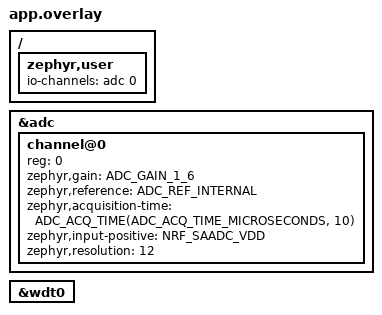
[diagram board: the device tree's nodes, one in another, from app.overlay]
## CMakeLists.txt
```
# SPDX-License-Identifier: Apache-2.0
cmake_minimum_required(VERSION 3.20.0)

# Плата holyiot_21011 описана в этом репозитории (boards/holyiot/holyiot_21011).
list(APPEND BOARD_ROOT ${CMAKE_CURRENT_SOURCE_DIR}/../..)

find_package(Zephyr REQUIRED HINTS $ENV{ZEPHYR_BASE})
project(knife_angle)

target_sources(app PRIVATE
  src/main.c
  src/accel.c
  src/ble.c
  src/calib.c
  src/filter.c
)
```

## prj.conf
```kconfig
# KnifeAngle: основная прошивка (этап 1).

# --- BLE: периферия, одно соединение, без сопряжения ---
CONFIG_BT=y
CONFIG_BT_PERIPHERAL=y
CONFIG_BT_DEVICE_NAME="KnifeAngle"
CONFIG_BT_MAX_CONN=1
CONFIG_BT_SMP=n
CONFIG_BT_BAS=y
# Без сопряжения шифрование и приватность в контроллере не нужны (минус ~10 КБ flash).
CONFIG_BT_CTLR_LE_ENC=n
CONFIG_BT_CTLR_PRIVACY=n

# Параметры соединения, которые устройство запрашивает через 5 с после подключения.
# Интервал 180–200 мс (единицы 1.25 мс): ровно под notify раз в 200 мс, и меньше
# пробуждений радио. Задержка 0, таймаут 4 с.
# Укладывается в требования Apple: min+15 мс ≤ max, max·(lat+1)·3 < timeout.
CONFIG_BT_GAP_AUTO_UPDATE_CONN_PARAMS=y
CONFIG_BT_GAP_PERIPHERAL_PREF_PARAMS=y
CONFIG_BT_PERIPHERAL_PREF_MIN_INT=144
CONFIG_BT_PERIPHERAL_PREF_MAX_INT=160
CONFIG_BT_PERIPHERAL_PREF_LATENCY=0
CONFIG_BT_PERIPHERAL_PREF_TIMEOUT=400

# --- Периферия чипа ---
CONFIG_SPI=y
# Драйвер Zephyr для LIS2DH не нужен: регистры читаются напрямую (accel.c).
CONFIG_LIS2DH=n
CONFIG_ADC=y
CONFIG_WATCHDOG=y
CONFIG_POWEROFF=y

# --- Хранение калибровки: NVS в разделе storage_partition (8 КБ) ---
CONFIG_FLASH=y
CONFIG_FLASH_MAP=y
CONFIG_NVS=y

# --- Прочее ---
CONFIG_LOG=n
CONFIG_ASSERT=n
CONFIG_MAIN_STACK_SIZE=2048
```

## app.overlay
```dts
/ {
	zephyr,user {
		io-channels = <&adc 0>;
	};
};

/* Канал 0 SAADC: напряжение питания VDD (батарея), шкала 0..3.6 В. */
&adc {
	#address-cells = <1>;
	#size-cells = <0>;

	channel@0 {
		reg = <0>;
		zephyr,gain = "ADC_GAIN_1_6";
		zephyr,reference = "ADC_REF_INTERNAL";
		zephyr,acquisition-time = <ADC_ACQ_TIME(ADC_ACQ_TIME_MICROSECONDS, 10)>;
		zephyr,input-positive = <NRF_SAADC_VDD>;
		zephyr,resolution = <12>;
	};
};

&wdt0 {
	status = "okay";
};
```

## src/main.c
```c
/*
 * KnifeAngle: BLE-датчик угла заточки (HOLYIOT-21011, nRF52810 + LIS2DH12).
 *
 * Состояния:
 *   ВЫКЛ: System OFF, датчик обесточен, радио выключено, пробуждение по кнопке.
 *         Пробуждение из System OFF это сброс чипа, поэтому после старта проверяется,
 *         что кнопку держат ≥1.5 с; если нет, чип сразу засыпает обратно.
 *         Любой другой сброс (установка батарейки, перепрошивка, watchdog) тоже ведёт в ВЫКЛ.
 *   ВКЛ:  датчик 25 Гц, реклама «KnifeAngle», при подключении notify угла 5 раз в секунду.
 *
 * Кнопка в ВКЛ: короткое нажатие (<0.8 с) = калибровка, длинное (≥1.5 с) = ВЫКЛ.
 * Светодиод: ВКЛ = одна вспышка 0.5 с, ВЫКЛ = две по 0.15 с,
 *            калибровка = короткая 60 мс, отказ калибровки = три быстрые.
 *
 * SPDX-License-Identifier: Apache-2.0
 */

#include <math.h>
#include <string.h>

#include <zephyr/kernel.h>
#include <zephyr/drivers/adc.h>
#include <zephyr/drivers/gpio.h>
#include <zephyr/drivers/watchdog.h>
#include <zephyr/sys/poweroff.h>
#include <zephyr/sys/util.h>
#include <hal/nrf_power.h>

#include "accel.h"
#include "app.h"
#include "ble.h"
#include "calib.h"
#include "filter.h"

/* Допустимый модуль вектора при калибровке, mg: датчик должен лежать спокойно. */
#define CALIB_MIN_MG 700.0f
#define CALIB_MAX_MG 1300.0f

#define WDT_TIMEOUT_MS 5000

#define RAD_TO_DEG 57.29577951f

static const struct gpio_dt_spec led = GPIO_DT_SPEC_GET(DT_ALIAS(led0), gpios);
static const struct gpio_dt_spec btn = GPIO_DT_SPEC_GET(DT_ALIAS(sw0), gpios);
static const struct adc_dt_spec vdd_adc = ADC_DT_SPEC_GET_BY_IDX(DT_PATH(zephyr_user), 0);
static const struct device *const wdt = DEVICE_DT_GET(DT_NODELABEL(wdt0));

K_MSGQ_DEFINE(evq, sizeof(uint8_t), 16, 1);

void app_post(enum app_event ev)
{
	uint8_t e = ev;

	(void)k_msgq_put(&evq, &e, K_NO_WAIT);
}

/* ------------------------------------------------------------------------ */
/* Светодиод, сторожевой таймер, батарея                                    */
/* ------------------------------------------------------------------------ */

static void led_flash(int n, int on_ms, int off_ms)
{
	for (int i = 0; i < n; i++) {
		gpio_pin_set_dt(&led, 1);
		k_msleep(on_ms);
		gpio_pin_set_dt(&led, 0);
		if (i + 1 < n) {
			k_msleep(off_ms);
		}
	}
}

static int wdt_channel = -1;

static void wdt_start(void)
{
	const struct wdt_timeout_cfg cfg = {
		.window = { .min = 0, .max = WDT_TIMEOUT_MS },
		.flags = WDT_FLAG_RESET_SOC,
	};

	if (!device_is_ready(wdt)) {
		return;
	}
	wdt_channel = wdt_install_timeout(wdt, &cfg);
	if (wdt_channel >= 0) {
		wdt_setup(wdt, WDT_OPT_PAUSE_HALTED_BY_DBG);
	}
}

static void wdt_kick(void)
{
	if (wdt_channel >= 0) {
		wdt_feed(wdt, wdt_channel);
	}
}

/* Грубая кривая разряда CR2032 под малой нагрузкой: мВ → %. */
static uint8_t battery_percent(int32_t mv)
{
	static const struct {
		int16_t mv;
		uint8_t pct;
	} curve[] = {
		{ 3000, 100 }, { 2900, 80 }, { 2800, 60 }, { 2700, 40 },
		{ 2600, 20 },  { 2500, 10 }, { 2400, 5 },  { 2000, 0 },
	};

	if (mv >= curve[0].mv) {
		return 100;
	}
	for (size_t i = 1; i < ARRAY_SIZE(curve); i++) {
		if (mv >= curve[i].mv) {
			int32_t span = curve[i - 1].mv - curve[i].mv;

			return curve[i].pct + (mv - curve[i].mv) *
				(curve[i - 1].pct - curve[i].pct) / span;
		}
	}
	return 0;
}

static void battery_update(void)
{
	int16_t sample;
	struct adc_sequence seq = {
		.buffer = &sample,
		.buffer_size = sizeof(sample),
	};
	int32_t mv;

	adc_sequence_init_dt(&vdd_adc, &seq);
	if (adc_read_dt(&vdd_adc, &seq) != 0) {
		return;
	}
	mv = sample;
	adc_raw_to_millivolts_dt(&vdd_adc, &mv);
	ble_set_battery(battery_percent(mv));
}

/* ------------------------------------------------------------------------ */
/* Кнопка                                                                   */
/* ------------------------------------------------------------------------ */

static int btn_level; /* после антидребезга; меняется только в debounce_handler */
static struct gpio_callback btn_cb;

static void debounce_handler(struct k_work *work)
{
	int level = gpio_pin_get_dt(&btn);

	if (level >= 0 && level != btn_level) {
		btn_level = level;
		app_post(level ? EV_BTN_DOWN : EV_BTN_UP);
	}
}

static K_WORK_DELAYABLE_DEFINE(debounce_work, debounce_handler);

static void btn_isr(const struct device *dev, struct gpio_callback *cb, uint32_t pins)
{
	k_work_reschedule(&debounce_work, K_MSEC(20));
}

static void long_press_expiry(struct k_timer *t)
{
	app_post(EV_BTN_LONG);
}

static K_TIMER_DEFINE(long_press_timer, long_press_expiry, NULL);

static void tick_expiry(struct k_timer *t)
{
	app_post(EV_TICK);
}

static K_TIMER_DEFINE(tick_timer, tick_expiry, NULL);

static bool button_pressed(void)
{
	return gpio_pin_get_dt(&btn) > 0;
}

/* ------------------------------------------------------------------------ */
/* ВЫКЛ                                                                     */
/* ------------------------------------------------------------------------ */

static bool ble_started;

static FUNC_NORETURN void power_off(bool confirm)
{
	k_timer_stop(&tick_timer);
	k_timer_stop(&long_press_timer);
	gpio_pin_interrupt_configure_dt(&btn, GPIO_INT_DISABLE);

	if (ble_started) {
		ble_stop();
	}
	accel_off();

	if (confirm) {
		led_flash(2, 150, 150);
	}

	/* System OFF просыпается по уровню, поэтому сначала ждём отпускания кнопки. */
	while (button_pressed()) {
		wdt_kick();
		k_msleep(20);
	}
	k_msleep(50);

	gpio_pin_interrupt_configure_dt(&btn, GPIO_INT_LEVEL_ACTIVE);
	sys_poweroff();
}

/* ------------------------------------------------------------------------ */
/* Угол                                                                     */
/* ------------------------------------------------------------------------ */

static float ref[3] = { 0.0f, 0.0f, 1.0f }; /* без калибровки: ось Z датчика */
static bool calibrated;
static bool sensor_error;

static void process_samples(void)
{
	int16_t buf[ACCEL_FIFO_DEPTH][3];
	int n;

	if (sensor_error) {
		return;
	}
	n = accel_read_fifo(buf, ACCEL_FIFO_DEPTH);
	if (n < 0) {
		sensor_error = true;
		return;
	}
	for (int i = 0; i < n; i++) {
		filter_add(buf[i]);
	}
}

/* Угол между текущим вектором гравитации и опорным, 0..180°, в единицах 0.1°.
 * atan2(|r×g|, r·g) точнее, чем acos, при углах около 0° и 180°.
 */
static int16_t angle_x10(const float g[3])
{
	float cx = ref[1] * g[2] - ref[2] * g[1];
	float cy = ref[2] * g[0] - ref[0] * g[2];
	float cz = ref[0] * g[1] - ref[1] * g[0];
	float cross = sqrtf(cx * cx + cy * cy + cz * cz);
	float dot = ref[0] * g[0] + ref[1] * g[1] + ref[2] * g[2];

	return (int16_t)lroundf(atan2f(cross, dot) * RAD_TO_DEG * 10.0f);
}

static void publish_angle(void)
{
	uint8_t flags = (calibrated ? ANGLE_FLAG_CALIBRATED : 0) |
			(sensor_error ? ANGLE_FLAG_SENSOR_ERROR : 0);
	float g[3];

	ble_set_angle(filter_get(g) ? angle_x10(g) : 0, flags);
}

static void calibrate(void)
{
	float m;
	float g[3];
	float v[3];

	process_samples(); /* взять самые свежие отсчёты из FIFO */

	if (sensor_error || !filter_get(g)) {
		led_flash(3, 40, 80);
		return;
	}
	m = sqrtf(g[0] * g[0] + g[1] * g[1] + g[2] * g[2]);
	if (m < CALIB_MIN_MG || m > CALIB_MAX_MG) {
		led_flash(3, 40, 80);
		return;
	}
	for (int a = 0; a < 3; a++) {
		v[a] = g[a] / m;
	}
	if (calib_save(v) != 0) {
		led_flash(3, 40, 80);
		return;
	}

	memcpy(ref, v, sizeof(ref));
	calibrated = true;
	led_flash(1, 60, 0);
	publish_angle();
}

/* ------------------------------------------------------------------------ */

static void set_tick(uint32_t period_ms)
{
	k_timer_start(&tick_timer, K_MSEC(period_ms), K_MSEC(period_ms));
}

int main(void)
{
	uint32_t resetreas = NRF_POWER->RESETREAS;
	int64_t press_start = 0;
	int64_t last_conn_activity;
	int64_t last_battery;
	bool ignore_release;
	uint8_t ev;

	NRF_POWER->RESETREAS = resetreas; /* сброс битов записью единиц */

	gpio_pin_configure_dt(&led, GPIO_OUTPUT_INACTIVE);
	gpio_pin_configure_dt(&btn, GPIO_INPUT);

	/* Не пробуждение кнопкой (батарейку вставили, перепрошили, сработал watchdog):
	 * устройство начинает в ВЫКЛ.
	 */
	if (!(resetreas & POWER_RESETREAS_OFF_Msk)) {
		power_off(false);
	}

	/* Пробуждение кнопкой: включаемся, только если её держат ≥1.5 с с момента старта. */
	while (k_uptime_get() < LONG_PRESS_MS) {
		if (!button_pressed()) {
			power_off(false);
		}
		k_msleep(10);
	}

	/* ---- ВКЛ ---- */
	wdt_start();
	led_flash(1, 500, 0);

	/* Нажатие, которым включили, ещё может длиться: его отпускание игнорируем. */
	btn_level = button_pressed();
	ignore_release = btn_level;
	gpio_init_callback(&btn_cb, btn_isr, BIT(btn.pin));
	gpio_add_callback_dt(&btn, &btn_cb);
	gpio_pin_interrupt_configure_dt(&btn, GPIO_INT_EDGE_BOTH);
	/* Перечитать уровень: кнопку могли отпустить до включения прерывания. */
	k_work_reschedule(&debounce_work, K_MSEC(20));

	calibrated = calib_load(ref);
	if (!calibrated) {
		ref[0] = 0.0f;
		ref[1] = 0.0f;
		ref[2] = 1.0f;
	}

	if (accel_on() != 0) {
		sensor_error = true;
		led_flash(5, 40, 120);
	}

	adc_channel_setup_dt(&vdd_adc);

	if (ble_init() != 0) {
		led_flash(10, 40, 80);
		power_off(false);
	}
	ble_started = true;
	battery_update();
	last_battery = k_uptime_get();
	ble_adv_start();

	last_conn_activity = k_uptime_get();
	set_tick(TICK_IDLE_MS);

	while (true) {
		k_msgq_get(&evq, &ev, K_FOREVER);
		int64_t now = k_uptime_get();

		switch (ev) {
		case EV_TICK:
			wdt_kick();
			process_samples();
			publish_angle();
			if (now - last_battery >= BATTERY_PERIOD_MS) {
				battery_update();
				last_battery = now;
			}
			if (!ble_is_connected() && now - last_conn_activity >= AUTO_OFF_NO_CONN_MS) {
				power_off(true);
			}
			break;

		case EV_BTN_DOWN:
			press_start = now;
			k_timer_start(&long_press_timer, K_MSEC(LONG_PRESS_MS), K_NO_WAIT);
			break;

		case EV_BTN_UP:
			k_timer_stop(&long_press_timer);
			if (ignore_release) {
				ignore_release = false;
			} else if (now - press_start < SHORT_PRESS_MS) {
				calibrate();
			}
			break;

		case EV_BTN_LONG:
			if (btn_level && !ignore_release) {
				power_off(true);
			}
			break;

		case EV_CALIBRATE:
			calibrate();
			break;

		case EV_CONNECTED:
			last_conn_activity = now;
			set_tick(TICK_CONNECTED_MS);
			break;

		case EV_DISCONNECTED:
			last_conn_activity = now;
			set_tick(TICK_IDLE_MS);
			break;

		case EV_ADV_RESTART:
			if (!ble_is_connected()) {
				ble_adv_start();
			}
			break;
		}
	}

	return 0;
}
```

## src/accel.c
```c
/*
 * LIS2DH12 по SPI.
 *
 * Датчик питается от P0.08 (LVCC). В ВЫКЛ питание снимается полностью, так что
 * в System OFF датчик ничего не потребляет.
 *
 * Отсчёты копятся во встроенном FIFO (32 уровня) в режиме stream, а прошивка
 * забирает их пачкой раз в 200 мс (при подключении) или раз в 1 с (без него).
 * Так процессор просыпается редко, а фильтр всё равно получает все 25 отсчётов в секунду.
 *
 * SPDX-License-Identifier: Apache-2.0
 */

#include <errno.h>

#include <zephyr/kernel.h>
#include <zephyr/drivers/gpio.h>
#include <zephyr/drivers/spi.h>
#include <zephyr/sys/byteorder.h>
#include <zephyr/sys/util.h>
#include <hal/nrf_gpio.h>

#include "accel.h"

#define REG_WHO_AM_I      0x0F
#define REG_CTRL_REG1     0x20
#define REG_CTRL_REG4     0x23
#define REG_CTRL_REG5     0x24
#define REG_OUT_X_L       0x28
#define REG_FIFO_CTRL_REG 0x2E
#define REG_FIFO_SRC_REG  0x2F

#define WHO_AM_I_VAL 0x33

#define SPI_READ  0x80
#define SPI_MULTI 0x40

/* Линии SPI по схеме (boards/holyiot/holyiot_21011/holyiot_21011-pinctrl.dtsi). */
#define PIN_SCK  5
#define PIN_MOSI 2
#define PIN_MISO 3

#define ACCEL_NODE DT_NODELABEL(lis2dh12)

/* LIS2DH12: SPI режим 3 (SCK в покое высокий), старший бит первым. */
static const struct spi_dt_spec spi = SPI_DT_SPEC_GET(
	ACCEL_NODE, SPI_WORD_SET(8) | SPI_TRANSFER_MSB | SPI_MODE_CPOL | SPI_MODE_CPHA);

static const struct gpio_dt_spec pwr = GPIO_DT_SPEC_GET(DT_PATH(zephyr_user), accel_power_gpios);

static int reg_read(uint8_t reg, uint8_t *buf, size_t len)
{
	uint8_t cmd = SPI_READ | (len > 1 ? SPI_MULTI : 0) | reg;
	const struct spi_buf tx_buf = { .buf = &cmd, .len = 1 };
	const struct spi_buf_set tx = { .buffers = &tx_buf, .count = 1 };
	struct spi_buf rx_bufs[] = {
		{ .buf = NULL, .len = 1 }, /* байт во время передачи команды */
		{ .buf = buf, .len = len },
	};
	const struct spi_buf_set rx = { .buffers = rx_bufs, .count = ARRAY_SIZE(rx_bufs) };

	return spi_transceive_dt(&spi, &tx, &rx);
}

static int reg_write(uint8_t reg, uint8_t val)
{
	uint8_t data[2] = { reg, val };
	const struct spi_buf tx_buf = { .buf = data, .len = sizeof(data) };
	const struct spi_buf_set tx = { .buffers = &tx_buf, .count = 1 };

	return spi_write_dt(&spi, &tx);
}

int accel_on(void)
{
	uint8_t who = 0;
	int err;

	if (!spi_is_ready_dt(&spi) || !gpio_is_ready_dt(&pwr)) {
		return -ENODEV;
	}

	gpio_pin_configure_dt(&pwr, GPIO_OUTPUT_ACTIVE);
	k_msleep(10); /* загрузка после подачи питания: 5 мс по даташиту */

	err = reg_read(REG_WHO_AM_I, &who, 1);
	if (err) {
		return err;
	}
	if (who != WHO_AM_I_VAL) {
		return -ENODEV;
	}

	/* Порядок: сначала FIFO в bypass (сброс), потом настройка, потом stream. */
	err = reg_write(REG_FIFO_CTRL_REG, 0x00);
	/* ±4 g, а не ±2 g: при штрихах гравитация плюс ускорение и вибрация от камня
	 * могут выйти за 2 g по оси, а срезанные пики смещают среднее.
	 */
	err |= reg_write(REG_CTRL_REG4, 0x98); /* BDU=1, ±4 g, HR=1 (12 бит, 2 mg/LSB) */
	err |= reg_write(REG_CTRL_REG5, 0x40); /* FIFO_EN */
	err |= reg_write(REG_FIFO_CTRL_REG, 0x80); /* stream: при переполнении старые отсчёты затираются */
	err |= reg_write(REG_CTRL_REG1, 0x37); /* ODR 25 Гц, X/Y/Z включены */

	return err ? -EIO : 0;
}

int accel_read_fifo(int16_t mg[][3], int max)
{
	uint8_t src;
	uint8_t raw[6];
	int n;

	if (reg_read(REG_FIFO_SRC_REG, &src, 1)) {
		return -EIO;
	}

	/* FSS: число непрочитанных отсчётов; OVRN: FIFO полон (32). */
	n = (src & BIT(6)) ? ACCEL_FIFO_DEPTH : (src & 0x1F);
	n = MIN(n, max);

	for (int i = 0; i < n; i++) {
		/* Чтение 6 байт с 0x28 забирает из FIFO один отсчёт X/Y/Z. */
		if (reg_read(REG_OUT_X_L, raw, sizeof(raw))) {
			return -EIO;
		}
		for (int a = 0; a < 3; a++) {
			/* Данные 12-битные, выровнены влево; 2 mg на единицу при ±4 g. */
			mg[i][a] = ((int16_t)sys_get_le16(&raw[2 * a]) >> 4) * 2;
		}
	}

	return n;
}

void accel_off(void)
{
	(void)reg_write(REG_CTRL_REG1, 0x00); /* power-down */

	/* Снять питание и отпустить все линии датчика: высокий уровень на CS или SCK
	 * при обесточенном датчике подпитывал бы его через защитные диоды.
	 */
	gpio_pin_configure_dt(&pwr, GPIO_OUTPUT_INACTIVE);
	gpio_pin_configure_dt(&spi.config.cs.gpio, GPIO_DISCONNECTED);
	nrf_gpio_cfg_default(PIN_SCK);
	nrf_gpio_cfg_default(PIN_MOSI);
	nrf_gpio_cfg_default(PIN_MISO);
}
```

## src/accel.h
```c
/*
 * LIS2DH12 по SPI: питание через GPIO, FIFO в режиме stream.
 * SPDX-License-Identifier: Apache-2.0
 */

#ifndef KNIFE_ACCEL_H_
#define KNIFE_ACCEL_H_

#include <stdint.h>

/* Частота выборки датчика, Гц. */
#define ACCEL_ODR_HZ 25

/* Ёмкость FIFO LIS2DH12. */
#define ACCEL_FIFO_DEPTH 32

/* Подать питание, проверить WHO_AM_I и запустить: 25 Гц, ±4 g, HR, FIFO stream. */
int accel_on(void);

/* Забрать накопленные отсчёты (mg) из FIFO. Возвращает их число (0..32) или <0. */
int accel_read_fifo(int16_t mg[][3], int max);

/* Перевести датчик в power-down, снять питание и отпустить линии SPI. */
void accel_off(void);

#endif /* KNIFE_ACCEL_H_ */
```

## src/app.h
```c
/*
 * KnifeAngle: общие определения.
 * SPDX-License-Identifier: Apache-2.0
 */

#ifndef KNIFE_APP_H_
#define KNIFE_APP_H_

#include <stdint.h>

/* Время без подключения до автоматического выключения. */
#define AUTO_OFF_NO_CONN_MS (10 * 60 * 1000)

/* Кнопка. */
#define LONG_PRESS_MS  1500 /* ВКЛ/ВЫКЛ */
#define SHORT_PRESS_MS 800  /* короче: калибровка */

/* Период обработки: при подключении это и период notify (5 Гц). */
#define TICK_CONNECTED_MS 200
#define TICK_IDLE_MS      1000 /* без подключения FIFO датчика (32 отсчёта = 1.28 с) читается реже */

/* Период измерения батареи. */
#define BATTERY_PERIOD_MS (60 * 1000)

/* Биты поля flags в характеристике Angle. */
#define ANGLE_FLAG_CALIBRATED   0x01
#define ANGLE_FLAG_SENSOR_ERROR 0x02

/* События главного цикла. */
enum app_event {
	EV_TICK,
	EV_BTN_DOWN,
	EV_BTN_UP,
	EV_BTN_LONG,
	EV_CALIBRATE,
	EV_CONNECTED,
	EV_DISCONNECTED,
	EV_ADV_RESTART,
};

void app_post(enum app_event ev);

#endif /* KNIFE_APP_H_ */
```

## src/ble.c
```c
/*
 * BLE: реклама «KnifeAngle», сервис с характеристиками Angle и Command, Battery Service.
 * SPDX-License-Identifier: Apache-2.0
 */

#include <errno.h>

#include <zephyr/kernel.h>
#include <zephyr/bluetooth/bluetooth.h>
#include <zephyr/bluetooth/conn.h>
#include <zephyr/bluetooth/gatt.h>
#include <zephyr/bluetooth/hci.h>
#include <zephyr/bluetooth/uuid.h>
#include <zephyr/bluetooth/services/bas.h>
#include <zephyr/sys/byteorder.h>

#include "app.h"
#include "ble.h"

static const struct bt_uuid_128 ka_svc_uuid = BT_UUID_INIT_128(KA_UUID_SVC_VAL);
static const struct bt_uuid_128 ka_angle_uuid = BT_UUID_INIT_128(KA_UUID_ANGLE_VAL);
static const struct bt_uuid_128 ka_cmd_uuid = BT_UUID_INIT_128(KA_UUID_COMMAND_VAL);

static uint8_t angle_val[3]; /* int16 LE угол ×10 + uint8 flags */
static bool notify_enabled;
static struct bt_conn *cur_conn;

static ssize_t angle_read(struct bt_conn *conn, const struct bt_gatt_attr *attr, void *buf,
			  uint16_t len, uint16_t offset)
{
	return bt_gatt_attr_read(conn, attr, buf, len, offset, angle_val, sizeof(angle_val));
}

static void angle_ccc_changed(const struct bt_gatt_attr *attr, uint16_t value)
{
	notify_enabled = (value == BT_GATT_CCC_NOTIFY);
}

static ssize_t cmd_write(struct bt_conn *conn, const struct bt_gatt_attr *attr, const void *buf,
			 uint16_t len, uint16_t offset, uint8_t flags)
{
	if (offset != 0 || len != 1) {
		return BT_GATT_ERR(BT_ATT_ERR_INVALID_ATTRIBUTE_LEN);
	}

	switch (((const uint8_t *)buf)[0]) {
	case KA_CMD_CALIBRATE:
		app_post(EV_CALIBRATE);
		return len;
	default:
		return BT_GATT_ERR(BT_ATT_ERR_VALUE_NOT_ALLOWED);
	}
}

BT_GATT_SERVICE_DEFINE(ka_svc,
	BT_GATT_PRIMARY_SERVICE(&ka_svc_uuid),
	BT_GATT_CHARACTERISTIC(&ka_angle_uuid.uuid, BT_GATT_CHRC_READ | BT_GATT_CHRC_NOTIFY,
			       BT_GATT_PERM_READ, angle_read, NULL, NULL),
	BT_GATT_CCC(angle_ccc_changed, BT_GATT_PERM_READ | BT_GATT_PERM_WRITE),
	BT_GATT_CUD("Angle", BT_GATT_PERM_READ),
	BT_GATT_CHARACTERISTIC(&ka_cmd_uuid.uuid,
			       BT_GATT_CHRC_WRITE | BT_GATT_CHRC_WRITE_WITHOUT_RESP,
			       BT_GATT_PERM_WRITE, NULL, cmd_write, NULL),
	BT_GATT_CUD("Command", BT_GATT_PERM_READ),
);

/* Индекс значения Angle в ka_svc.attrs: 0 сервис, 1 объявление, 2 значение. */
#define ANGLE_ATTR (&ka_svc.attrs[2])

static const struct bt_data ad[] = {
	BT_DATA_BYTES(BT_DATA_FLAGS, (BT_LE_AD_GENERAL | BT_LE_AD_NO_BREDR)),
	BT_DATA(BT_DATA_NAME_COMPLETE, CONFIG_BT_DEVICE_NAME, sizeof(CONFIG_BT_DEVICE_NAME) - 1),
};

/* UUID сервиса не помещается в рекламный пакет вместе с именем и идёт в ответе на скан. */
static const struct bt_data sd[] = {
	BT_DATA_BYTES(BT_DATA_UUID128_ALL, KA_UUID_SVC_VAL),
};

static const struct bt_le_adv_param adv_param =
	BT_LE_ADV_PARAM_INIT(BT_LE_ADV_OPT_CONN, ADV_INTERVAL_MIN, ADV_INTERVAL_MAX, NULL);

static void connected(struct bt_conn *conn, uint8_t err)
{
	if (err) {
		app_post(EV_ADV_RESTART);
		return;
	}
	cur_conn = bt_conn_ref(conn);
	app_post(EV_CONNECTED);
}

static void disconnected(struct bt_conn *conn, uint8_t reason)
{
	if (cur_conn) {
		bt_conn_unref(cur_conn);
		cur_conn = NULL;
	}
	notify_enabled = false;
	app_post(EV_DISCONNECTED);
}

/* Объект соединения освобождён: только теперь можно снова начать рекламу. */
static void recycled(void)
{
	app_post(EV_ADV_RESTART);
}

BT_CONN_CB_DEFINE(conn_callbacks) = {
	.connected = connected,
	.disconnected = disconnected,
	.recycled = recycled,
};

int ble_init(void)
{
	return bt_enable(NULL);
}

int ble_adv_start(void)
{
	int err = bt_le_adv_start(&adv_param, ad, ARRAY_SIZE(ad), sd, ARRAY_SIZE(sd));

	return (err == -EALREADY) ? 0 : err;
}

void ble_stop(void)
{
	bt_le_adv_stop();
	if (cur_conn) {
		bt_conn_disconnect(cur_conn, BT_HCI_ERR_REMOTE_USER_TERM_CONN);
		/* Дать контроллеру отправить LL_TERMINATE_IND, чтобы страница сразу
		 * увидела отключение, а не ждала таймаута супервизии (4 с).
		 */
		for (int i = 0; i < 50 && cur_conn; i++) {
			k_msleep(10);
		}
	}
}

bool ble_is_connected(void)
{
	return cur_conn != NULL;
}

void ble_set_angle(int16_t angle_x10, uint8_t flags)
{
	sys_put_le16((uint16_t)angle_x10, angle_val);
	angle_val[2] = flags;

	if (cur_conn && notify_enabled) {
		(void)bt_gatt_notify(cur_conn, ANGLE_ATTR, angle_val, sizeof(angle_val));
	}
}

void ble_set_battery(uint8_t percent)
{
	(void)bt_bas_set_battery_level(percent);
}
```

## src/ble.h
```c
/*
 * BLE: реклама, сервис KnifeAngle, служба батареи.
 * SPDX-License-Identifier: Apache-2.0
 */

#ifndef KNIFE_BLE_H_
#define KNIFE_BLE_H_

#include <stdbool.h>
#include <stdint.h>

/*
 * Сервис KnifeAngle (UUID сгенерированы случайно):
 *   сервис  8c900001-4d19-4014-a48c-3f940a276aeb
 *   Angle   8c900002-4d19-4014-a48c-3f940a276aeb  read, notify: int16 LE (0.1°) + uint8 flags
 *   Command 8c900003-4d19-4014-a48c-3f940a276aeb  write: 0x01 = калибровка
 */
#define KA_UUID_SVC_VAL     BT_UUID_128_ENCODE(0x8c900001, 0x4d19, 0x4014, 0xa48c, 0x3f940a276aeb)
#define KA_UUID_ANGLE_VAL   BT_UUID_128_ENCODE(0x8c900002, 0x4d19, 0x4014, 0xa48c, 0x3f940a276aeb)
#define KA_UUID_COMMAND_VAL BT_UUID_128_ENCODE(0x8c900003, 0x4d19, 0x4014, 0xa48c, 0x3f940a276aeb)

#define KA_CMD_CALIBRATE 0x01

/* Реклама: интервал 852.5–875 мс (единицы 0.625 мс). 852.5 мс входит в список
 * интервалов, которые Apple рекомендует для быстрого обнаружения на iOS.
 */
#define ADV_INTERVAL_MIN 1364
#define ADV_INTERVAL_MAX 1400

int ble_init(void);
int ble_adv_start(void);
void ble_stop(void);
bool ble_is_connected(void);

/* Обновить значение Angle и, если клиент подписан, отправить notify. */
void ble_set_angle(int16_t angle_x10, uint8_t flags);

void ble_set_battery(uint8_t percent);

#endif /* KNIFE_BLE_H_ */
```

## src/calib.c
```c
/*
 * Калибровка в NVS (раздел storage_partition, последние 8 КБ flash).
 *
 * Переживает выключение и замену батарейки. Стирается только полным стиранием
 * чипа (Erase nRF) при перепрошивке.
 *
 * SPDX-License-Identifier: Apache-2.0
 */

#include <string.h>

#include <zephyr/kernel.h>
#include <zephyr/drivers/flash.h>
#include <zephyr/kvss/nvs.h>
#include <zephyr/storage/flash_map.h>

#include "calib.h"

#define CALIB_NVS_ID 1
#define CALIB_MAGIC  0x4B414C31 /* "KAL1": формат записи, версия 1 */

struct calib_record {
	uint32_t magic;
	float ref[3];
};

static struct nvs_fs fs;
static bool mounted;

static int calib_mount(void)
{
	struct flash_pages_info info;
	int err;

	if (mounted) {
		return 0;
	}

	fs.flash_device = PARTITION_DEVICE(storage_partition);
	if (!device_is_ready(fs.flash_device)) {
		return -ENODEV;
	}
	fs.offset = PARTITION_OFFSET(storage_partition);
	err = flash_get_page_info_by_offs(fs.flash_device, fs.offset, &info);
	if (err) {
		return err;
	}
	fs.sector_size = info.size;
	fs.sector_count = PARTITION_SIZE(storage_partition) / info.size;

	err = nvs_mount(&fs);
	if (err == 0) {
		mounted = true;
	}
	return err;
}

bool calib_load(float ref[3])
{
	struct calib_record rec;

	if (calib_mount() != 0) {
		return false;
	}
	if (nvs_read(&fs, CALIB_NVS_ID, &rec, sizeof(rec)) != sizeof(rec) ||
	    rec.magic != CALIB_MAGIC) {
		return false;
	}
	memcpy(ref, rec.ref, sizeof(rec.ref));
	return true;
}

int calib_save(const float ref[3])
{
	struct calib_record rec = { .magic = CALIB_MAGIC };
	ssize_t ret;
	int err;

	err = calib_mount();
	if (err) {
		return err;
	}
	memcpy(rec.ref, ref, sizeof(rec.ref));

	/* NVS не пишет запись, если значение не изменилось, и сам распределяет износ. */
	ret = nvs_write(&fs, CALIB_NVS_ID, &rec, sizeof(rec));
	return ret < 0 ? (int)ret : 0;
}
```

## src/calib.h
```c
/*
 * Калибровка: опорный вектор гравитации «нож плашмя на камне», хранится в NVS.
 * SPDX-License-Identifier: Apache-2.0
 */

#ifndef KNIFE_CALIB_H_
#define KNIFE_CALIB_H_

#include <stdbool.h>

/* Подключить NVS и прочитать сохранённый вектор. true, если калибровка есть. */
bool calib_load(float ref[3]);

/* Сохранить вектор. 0 при успехе. */
int calib_save(const float ref[3]);

#endif /* KNIFE_CALIB_H_ */
```

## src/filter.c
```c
/*
 * Оценка вектора гравитации, устойчивая к штрихам.
 *
 * Акселерометр меряет сумму гравитации и линейного ускорения и сам их не различает.
 * Штрих по камню даёт 0.1–0.5 g ускорения вдоль камня, и короткое среднее
 * показывает угол с ошибкой 5–25°. Но у штрихов есть два свойства:
 *   1. Нож начинает и кончает штрих в покое, поэтому за несколько штрихов
 *      ускорение в среднем почти нулевое.
 *   2. Ускорение меняется быстро и в одной плоскости (плоскость камня), и разброс
 *      отсчётов в этих направлениях большой. В покое разброс равен шуму, ~1–2 mg.
 *
 * Поэтому три оценки:
 *   fast: экспоненциальное среднее τ = 80 мс: быстрое и точное, пока датчик неподвижен;
 *   slow: два последовательных экспоненциальных средних по τ = 0.8 с: ускорения
 *         штрихов в нём взаимно гасятся (двойное звено гасит их заметно лучше одинарного);
 *   cov:  ковариация отсчётов с забыванием τ = 0.5 с: в каких направлениях и насколько
 *         вектор сейчас «гуляет».
 * Результат: slow + K·(fast − slow), где K = ε²·(cov + ε²·I)⁻¹.
 * В покое cov ≈ 0, K ≈ I, результат равен fast. При движении составляющие разности
 * (fast − slow) в направлениях с разбросом σ² ≫ ε² подавляются в σ²/ε² раз,
 * и результат стремится к slow. Порогов и переключения режимов нет, переход плавный.
 *
 * Цена: быстрый поворот рукой тоже выглядит как движение. После поворота на 10°
 * за 1 с показание догоняет примерно за 2 с (было 0.25 с), после плавной
 * подстройки на 2–3° примерно за 0.5 с.
 *
 * SPDX-License-Identifier: Apache-2.0
 */

#include <string.h>

#include "filter.h"

/* α = 1 − exp(−Δt/τ) при Δt = 40 мс (25 Гц). */
#define ALPHA_FAST 0.39f   /* τ = 80 мс */
#define ALPHA_SLOW 0.0488f /* τ = 0.8 с, два звена */
#define ALPHA_COV  0.0769f /* τ = 0.5 с */

/* Порог разброса ε = 30 mg. Шум датчика в покое ~1–2 mg, штрихи дают 50–500 mg. */
#define EPS2 (30.0f * 30.0f)

static bool have_sample;
static float fast[3];
static float slow1[3];
static float slow2[3];
static float cmean[3];
static float cov[6]; /* xx, yy, zz, xy, xz, yz; mg² */

void filter_add(const int16_t mg[3])
{
	const float k = 1.0f - ALPHA_COV;
	float d[3];

	if (!have_sample) {
		for (int a = 0; a < 3; a++) {
			fast[a] = slow1[a] = slow2[a] = cmean[a] = mg[a];
		}
		memset(cov, 0, sizeof(cov));
		have_sample = true;
		return;
	}

	for (int a = 0; a < 3; a++) {
		float v = mg[a];

		fast[a] += ALPHA_FAST * (v - fast[a]);
		slow1[a] += ALPHA_SLOW * (v - slow1[a]);
		slow2[a] += ALPHA_SLOW * (slow1[a] - slow2[a]);
		d[a] = v - cmean[a];
		cmean[a] += ALPHA_COV * d[a];
	}

	/* Ковариация с экспоненциальным окном (аналог алгоритма Уэлфорда). */
	cov[0] = k * (cov[0] + ALPHA_COV * d[0] * d[0]);
	cov[1] = k * (cov[1] + ALPHA_COV * d[1] * d[1]);
	cov[2] = k * (cov[2] + ALPHA_COV * d[2] * d[2]);
	cov[3] = k * (cov[3] + ALPHA_COV * d[0] * d[1]);
	cov[4] = k * (cov[4] + ALPHA_COV * d[0] * d[2]);
	cov[5] = k * (cov[5] + ALPHA_COV * d[1] * d[2]);
}

bool filter_get(float g[3])
{
	/* M = cov + ε²·I: симметричная, собственные числа ≥ ε², поэтому обратима. */
	float a = cov[0] + EPS2, b = cov[1] + EPS2, c = cov[2] + EPS2;
	float d = cov[3], e = cov[4], f = cov[5];
	/* Присоединённая матрица M (тоже симметричная). */
	float m00 = b * c - f * f;
	float m01 = e * f - d * c;
	float m02 = d * f - b * e;
	float m11 = a * c - e * e;
	float m12 = d * e - a * f;
	float m22 = a * b - d * d;
	float det = a * m00 + d * m01 + e * m02;
	float s = EPS2 / det;
	float r[3];

	if (!have_sample) {
		return false;
	}

	for (int i = 0; i < 3; i++) {
		r[i] = fast[i] - slow2[i];
	}
	g[0] = slow2[0] + s * (m00 * r[0] + m01 * r[1] + m02 * r[2]);
	g[1] = slow2[1] + s * (m01 * r[0] + m11 * r[1] + m12 * r[2]);
	g[2] = slow2[2] + s * (m02 * r[0] + m12 * r[1] + m22 * r[2]);

	return true;
}
```

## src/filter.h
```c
/*
 * Оценка вектора гравитации по отсчётам акселерометра, устойчивая к штрихам.
 * SPDX-License-Identifier: Apache-2.0
 */

#ifndef KNIFE_FILTER_H_
#define KNIFE_FILTER_H_

#include <stdbool.h>
#include <stdint.h>

/* Добавить отсчёт (mg). Вызывать для каждого отсчёта с частотой ACCEL_ODR_HZ. */
void filter_add(const int16_t mg[3]);

/* Текущая оценка вектора гравитации, mg. false, если отсчётов ещё не было. */
bool filter_get(float g[3]);

#endif /* KNIFE_FILTER_H_ */
```
